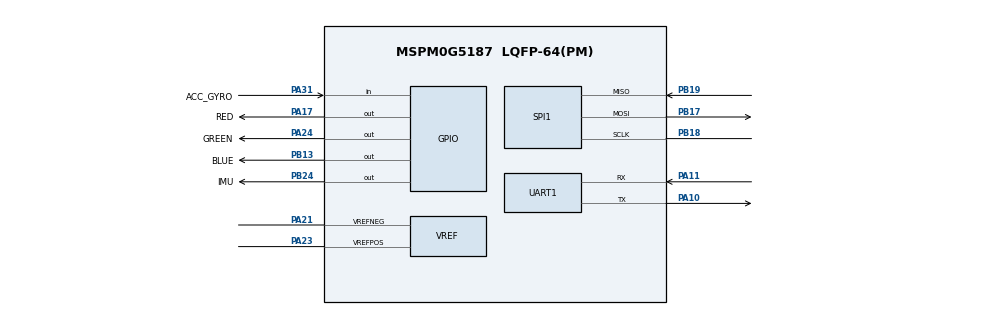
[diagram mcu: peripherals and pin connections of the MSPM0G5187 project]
//@cliArgs --device "MSPM0G518X" --package "LQFP-64(PM)" --part "Default"
//@v2CliArgs --device "MSPM0G5187" --package "LQFP-64(PM)"
// @cliArgs --board /ti/boards/LP_MSPM0G5187 --rtos nortos

/**
 * Import the modules used in this configuration.
 */
const GPIO          = scripting.addModule("/ti/driverlib/GPIO", {}, false);
const GPIO1         = GPIO.addInstance();
const GPIO2         = GPIO.addInstance();
const GPIO3         = GPIO.addInstance();
const SPI           = scripting.addModule("/ti/driverlib/SPI", {}, false);
const SPI1          = SPI.addInstance();
const SYSCTL        = scripting.addModule("/ti/driverlib/SYSCTL");
const UART          = scripting.addModule("/ti/driverlib/UART", {}, false);
const UART1         = UART.addInstance();
const VREF          = scripting.addModule("/ti/driverlib/VREF");
const ProjectConfig = scripting.addModule("/ti/project_config/ProjectConfig");

/**
 * Write custom configuration values to the imported modules.
 */
const divider7       = system.clockTree["PLL_PDIV"];
divider7.divideValue = 2;

const divider9       = system.clockTree["UDIV"];
divider9.divideValue = 2;

const multiplier2         = system.clockTree["PLL_QDIV"];
multiplier2.multiplyValue = 5;

const mux7       = system.clockTree["HSCLKMUX"];
mux7.inputSelect = "HSCLKMUX_SYSPLL2X";

GPIO1.$name                         = "SENSOR_INTR";
GPIO1.associatedPins[0].$name       = "ACC_GYRO";
GPIO1.associatedPins[0].direction   = "INPUT";
GPIO1.associatedPins[0].interruptEn = true;
GPIO1.associatedPins[0].polarity    = "FALL";
GPIO1.associatedPins[0].pin.$assign = "PA31";

const Board = scripting.addModule("/ti/driverlib/Board", {}, false);

GPIO2.$name                          = "CS";
GPIO2.associatedPins[0].$name        = "IMU";
GPIO2.associatedPins[0].initialValue = "SET";
GPIO2.associatedPins[0].pin.$assign  = "PB24";

GPIO3.$name                         = "LED";
GPIO3.associatedPins.create(3);
GPIO3.associatedPins[0].$name       = "GREEN";
GPIO3.associatedPins[0].pin.$assign = "PA24";
GPIO3.associatedPins[1].$name       = "RED";
GPIO3.associatedPins[1].pin.$assign = "PA17";
GPIO3.associatedPins[2].$name       = "BLUE";
GPIO3.associatedPins[2].pin.$assign = "PB13";

SPI1.$name                              = "SPI";
SPI1.targetBitRate                      = 1000000;
SPI1.frameFormat                        = "MOTO3";
SPI1.peripheral.$assign                 = "UC2";
SPI1.peripheral.sclkPin.$assign         = "PB18";
SPI1.peripheral.mosiPin.$assign         = "PB17";
SPI1.peripheral.misoPin.$assign         = "PB19";

SYSCTL.forceDefaultClkConfig = true;
SYSCTL.clockTreeEn           = true;

UART1.$name                             = "UART_DAP";
UART1.targetBaudRate                    = 115200;
UART1.enableFIFO                        = true;
UART1.rxFifoThreshold                   = "DL_UART_RX_FIFO_LEVEL_ONE_ENTRY";
UART1.txFifoThreshold                   = "DL_UART_TX_FIFO_LEVEL_3_4_EMPTY";
UART1.enabledDMARXTriggers              = "DL_UART_DMA_INTERRUPT_RX";
UART1.enabledDMATXTriggers              = "DL_UART_DMA_INTERRUPT_TX";
UART1.peripheral.$assign                = "UC0";
UART1.peripheral.rxPin.$assign          = "PA11";
UART1.peripheral.txPin.$assign          = "PA10";
UART1.DMA_CHANNEL_RX.$name              = "DMA_CH0";
UART1.DMA_CHANNEL_RX.addressMode        = "f2b";
UART1.DMA_CHANNEL_RX.srcLength          = "BYTE";
UART1.DMA_CHANNEL_RX.dstLength          = "BYTE";
UART1.DMA_CHANNEL_RX.peripheral.$assign = "DMA_CH0";
UART1.DMA_CHANNEL_TX.$name              = "DMA_CH1";
UART1.DMA_CHANNEL_TX.addressMode        = "b2f";
UART1.DMA_CHANNEL_TX.srcLength          = "BYTE";
UART1.DMA_CHANNEL_TX.dstLength          = "BYTE";
UART1.DMA_CHANNEL_TX.enableInterrupt    = true;
UART1.DMA_CHANNEL_TX.peripheral.$assign = "DMA_CH1";

VREF.basicMode                     = "DL_VREF_ENABLE_ENABLE_DL_VREF_ENABLE_DISABLE";
VREF.basicVrefPins                 = "VREF+-";
VREF.basicExtVolt                  = 3.3;
VREF.peripheral.$assign            = "VREF";
VREF.peripheral.vrefPosPin.$assign = "PA23";
VREF.peripheral.vrefNegPin.$assign = "PA21";
ProjectConfig.genLibNPU = true;
